# LPC11Axx register map
File version: 0.6
CPU: CM0 r0p0, little endian, no MPU, no FPU, 0x2 interrupt priority bits, 0x0 interrupts
Registers are 32-bit, read-write, reset 0x0 unless marked. A register's access mark holds for its fields unless they carry their own. Offsets are from the block's base; [hi:lo] are bit positions; {n}, {i} and the like mark numbered series.

## FMC — Flash controller
Base 0x4003C000
0x10 FLASHCFG reset not defined — Flash memory access time configuration register
  [1:0] FLASHTIM — Flash memory access time. FLASHTIM +1 is equal to the number of system clocks used for flash access.
    0=1_SYSTEM_CLOCK_FLASH (1 system clock flash access time (for system clock frequencies of up to 20 MHz).); 1=2_SYSTEM_CLOCKS_FLAS (2 system clocks flash access time (for system clock frequencies of up to 40 MHz).); 2=3_SYSTEM_CLOCKS_FLAS (3 system clocks flash access time (for system clock frequencies of up to 50 MHz).)
0x20 FMSSTART — Signature start address register
  [16:0] START — Signature generation start address (corresponds to AHB byte address bits[20:4]).
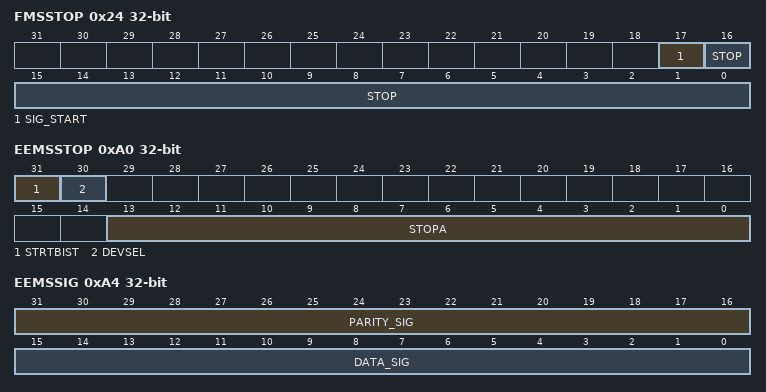
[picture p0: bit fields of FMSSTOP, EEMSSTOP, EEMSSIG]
0x24 FMSSTOP — Signature stop-address register
  [17] SIG_START — Start control bit for signature generation.
    0=SIGNATURE_GENERATION (Signature generation is stopped); 1=INITIATE_SIGNATURE_G (Initiate signature generation)
  [16:0] STOP — BIST stop address divided by 16 (corresponds to AHB byte address [20:4]).
{0x2C+4i} FMSW{i} ro reset not defined (i=0..3) — Word {i} [{32i+31}:{32i}]
  [31:0] SW{i}_{32i+31}_{32i} — Word {i} of 128-bit signature (bits {32i+31} to {32i}).
0x9C EEMSSTART — EEPROM BIST start address register
  [13:0] STARTA — BIST start address: Bit 0 is fixed zero since only even addresses are allowed.
0xA0 EEMSSTOP — EEPROM BIST stop address register
  [31] STRTBIST — BIST start bit Setting this bit will start the BIST. This bit is self-clearing.
  [30] DEVSEL — BIST device select bit 0: the BIST signature is generated over the total memory space. Singe pages are interleaved over the EEPROM devices when multiple devices are used, the signature is generated over memory of multiple devices. 1: the BIST signature is generated only over a memory range located on a single EEPROM device. Therefore the internal address generation is done such that the address' CS bits are kept stable to select only the same device. The address' MSB and LSB bits are used to step through the memory range specified by the start and stop address fields. Note: if this bit is set the start and stop address fields must be programmed such that they both address the same EEPROM device. Therefore the address' CS bits in both the start and stop address must be the same.
  [13:0] STOPA — BIST stop address: Bit 0 is fixed zero since only even addresses are allowed.
0xA4 EEMSSIG ro — EEPROM 24-bit BIST signature register
  [31:16] PARITY_SIG — BIST 16-bit signature calculated from only the parity bits of the data bytes
  [15:0] DATA_SIG — BIST 16-bit signature calculated from only the data bytes
0xFE0 FMSTAT ro — Signature generation status register
  [2] SIG_DONE — When 1, a previously started signature generation has completed. See FMSTATCLR register description for clearing this flag.
0xFE8 FMSTATCLR wo reset not defined — Signature generation status clear register
  [2] SIG_DONE_CLR — Writing a 1 to this bits clears the signature generation completion flag (SIG_DONE) in the FMSTAT register.

## GPIO_PIN_INT — GPIO Modification
Base 0x4004C000
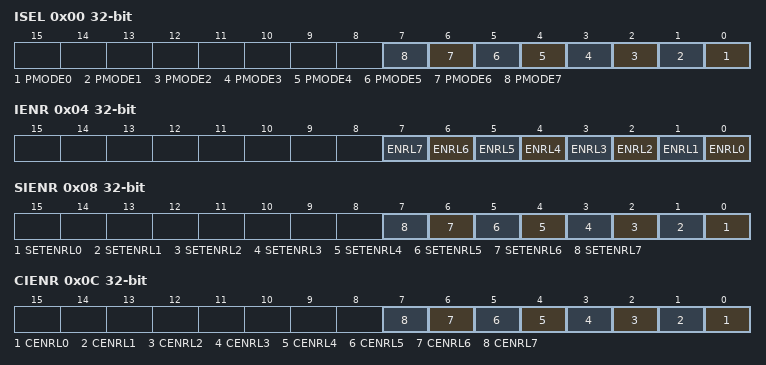
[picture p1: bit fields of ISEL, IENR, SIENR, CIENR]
0x00 ISEL — Pin Interrupt Mode register
  [n] PMODE{n} (n=0..7) — Selects the interrupt mode for each pin interrupt. Bit n configures the pin interrupt selected in PINTSELn. 0 = Edge sensitive 1 = Level sensitive
0x04 IENR — Pin Interrupt Enable (Rising) register
  [n] ENRL{n} (n=0..7) — Enables the rising edge or level interrupt for each pin interrupt. Bit n configures the pin interrupt selected in PINTSELn. 0 = Disable rising edge or level interrupt. 1 = Enable rising edge or level interrupt.
0x08 SIENR wo reset not defined — Set Pin Interrupt Enable (Rising) register
  [n] SETENRL{n} (n=0..7) — Ones written to this address set bits in the PINTEN_R, thus enabling interrupts. Bit n sets bit n in the PINTEN_R register. 0 = No operation. 1 = Enable rising edge or level interrupt.
0x0C CIENR wo reset not defined — Clear Pin Interrupt Enable (Rising) register
  [n] CENRL{n} (n=0..7) — Ones written to this address clear bits in the IENR, thus disabling the interrupts. Bit n clears bit n in the IENR register. 0 = No operation. 1 = Disable rising edge or level interrupt.
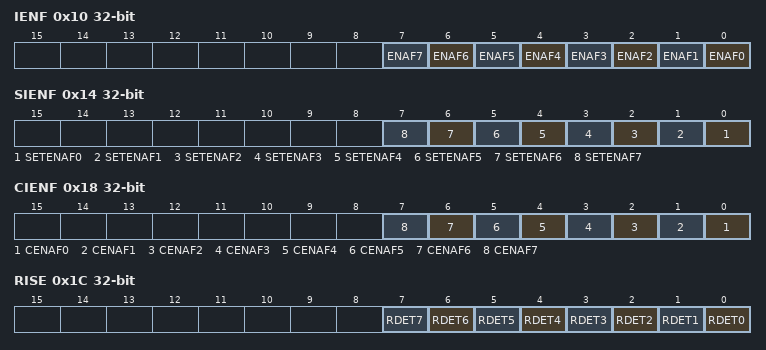
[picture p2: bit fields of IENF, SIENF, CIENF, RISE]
0x10 IENF — Pin Interrupt Enable Falling Edge / Active Level register
  [n] ENAF{n} (n=0..7) — Enables the falling edge or configures the active level interrupt for each pin interrupt. Bit n configures the pin interrupt selected in PINTSELn. 0 = Disable falling edge interrupt or set active interrupt level LOW. 1 = Enable falling edge interrupt enabled or set active interrupt level HIGH.
0x14 SIENF wo reset not defined — Set Pin Interrupt Enable Falling Edge / Active Level register
  [n] SETENAF{n} (n=0..7) — Ones written to this address set bits in the IENF, thus enabling interrupts. Bit n sets bit n in the IENF register. 0 = No operation. 1 = Select HIGH-active interrupt or enable falling edge interrupt.
0x18 CIENF wo reset not defined — Clear Pin Interrupt Enable Falling Edge / Active Level address
  [n] CENAF{n} (n=0..7) — Ones written to this address clears bits in the IENF, thus disabling interrupts. Bit n clears bit n in the IENF register. 0 = No operation. 1 = LOW-active interrupt selected or falling edge interrupt disabled.
0x1C RISE — Pin Interrupt Rising Edge register
  [n] RDET{n} (n=0..7) — Rising edge detect. Bit n detects the rising edge of the pin selected in PINTSELn. Read 0: No rising edge has been detected on this pin since Reset or the last time a one was written to this bit. Write 0: no operation. Read 1: a rising edge has been detected since Reset or the last time a one was written to this bit. Write 1: clear rising edge detection for this pin.
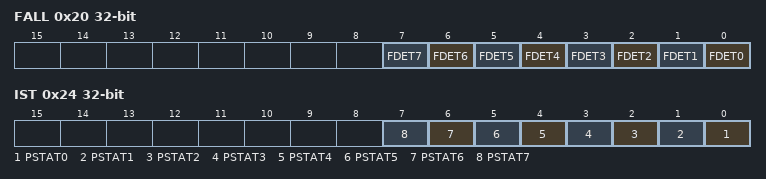
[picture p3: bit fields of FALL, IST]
0x20 FALL — Pin Interrupt Falling Edge register
  [n] FDET{n} (n=0..7) — Falling edge detect. Bit n detects the falling edge of the pin selected in PINTSELn. Read 0: No falling edge has been detected on this pin since Reset or the last time a one was written to this bit. Write 0: no operation. Read 1: a falling edge has been detected since Reset or the last time a one was written to this bit. Write 1: clear falling edge detection for this pin.
0x24 IST — Pin Interrupt Status register
  [n] PSTAT{n} (n=0..7) — Pin interrupt status. Bit n returns the status, clears the edge interrupt, or inverts the active level of the pin selected in PINTSELn. Read 0: interrupt is not being requested for this interrupt pin. Write 0: no operation. Read 1: interrupt is being requested for this interrupt pin. Write 1 (edge-sensitive): clear rising- and falling-edge detection for this pin. Write 1 (level-sensitive): switch the active level for this pin (in the PINTENT_F register).
